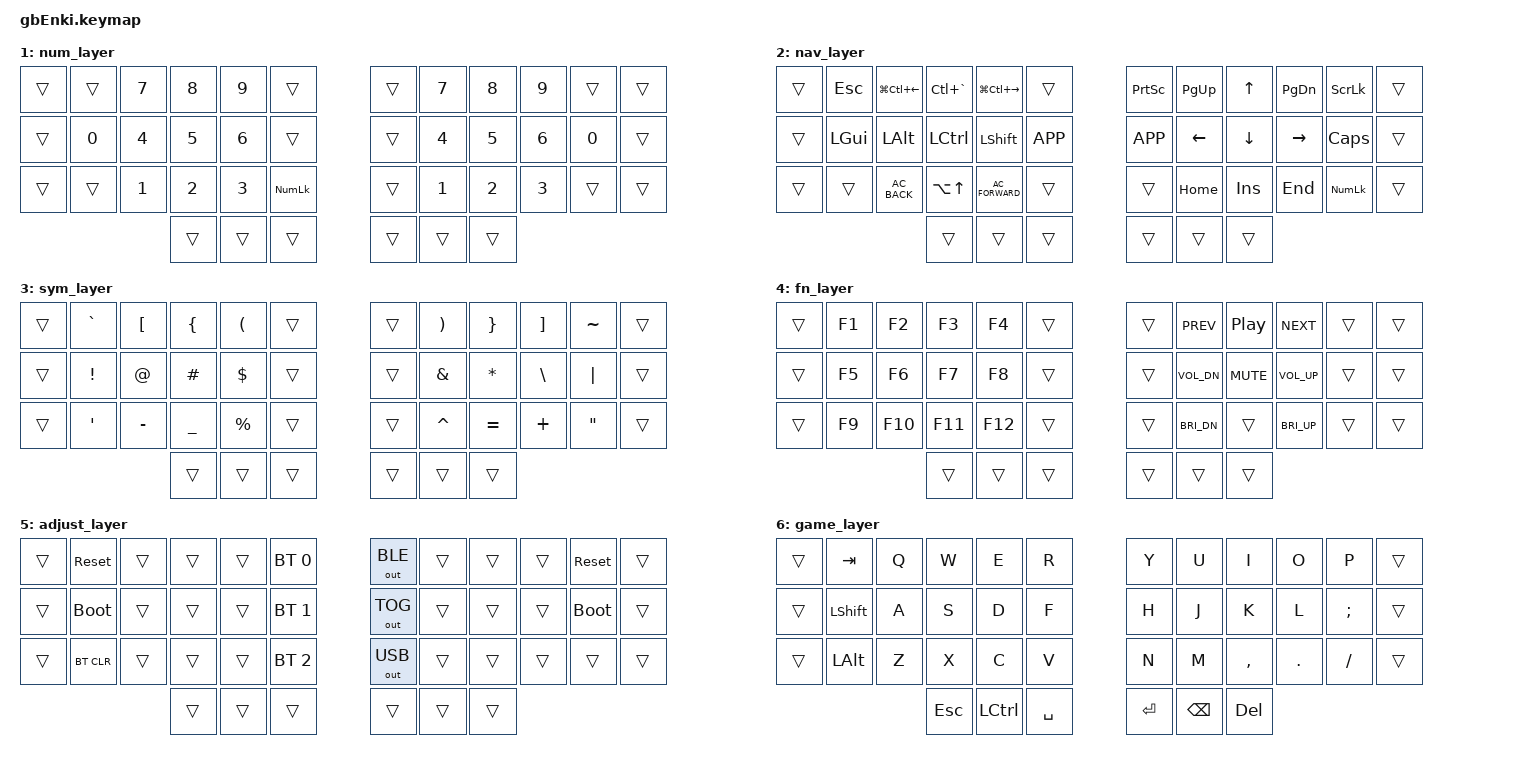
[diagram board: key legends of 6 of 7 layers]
// Copyright (c) 2022 The ZMK Contributors
// SPDX-License-Identifier: MIT

#include <behaviors.dtsi>
#include <dt-bindings/zmk/keys.h>
#include <dt-bindings/zmk/bt.h>
#include <dt-bindings/zmk/outputs.h>
#include <dt-bindings/zmk/ext_power.h>

#define HRML(k1,k2,k3,k4) &ht LGUI k1  &ht LALT k2  &ht LCTRL k3  &ht LSHFT k4
#define HRMR(k1,k2,k3,k4) &ht RSHFT k1  &ht RCTRL k2  &ht RALT k3  &ht RGUI k4
#define TERM &kp LC(GRAVE)
#define TASK_V &kp LG(TAB)
#define DESK_P &kp LG(LC(LEFT))
#define DESK_N &kp LG(LC(RIGHT))

#define COMBO(NAME, BINDINGS, KEYPOS, LAYERS) \
    combo_##NAME { \
        timeout-ms = <50>; \
        bindings = <BINDINGS>; \
        key-positions = <KEYPOS>; \
        layers = <LAYERS>; \
    };

/ {
    behaviors {
        ht: hold_tap {
            label = "hold_tap";
            compatible = "zmk,behavior-hold-tap";
            #binding-cells = <2>;
            flavor = "tap-preferred";
            tapping-term-ms = <150>;
            quick-tap-ms = <250>;
            bindings = <&kp>, <&kp>;
        };
        tt: thumb_hold_tap {
            label = "thumb_hold_tap";
            compatible = "zmk,behavior-hold-tap";
            #binding-cells = <2>;
            flavor = "tap-preferred";
            tapping_term_ms = <150>;
            quick_tap_ms = <250>;
            bindings = <&mo>, <&kp>;
        };
    };

    conditional_layers {
        compatible = "zmk,conditional-layers";
        adjust_layer {
            if-layers = <2 3>;
            then-layer = <5>;
        };
    };

        //╭──────╭──────┬──────┬──────┬──────┬──────╮   ╭──────┬──────┬──────┬──────┬──────╮──────╮
        //│  0   │  1   │  2   │  3   │  4   │  5   │   │  6   │  7   │  8   │  9   │  10  │  11  │
        //├──────├──────┼──────┼──────┼──────┼──────┤   ├──────┼──────┼──────┼──────┼──────┤──────┤
        //│  12  │  13  │  14  │  15  │  16  │  17  │   │  18  │  19  │  20  │  21  │  22  │  23  │
        //├──────├──────┼──────┼──────┼──────┼──────┤   ├──────┼──────┼──────┼──────┼──────┤──────┤
        //│  24  │  25  │  26  │  27  │  28  │  29  │   │  30  │  31  │  32  │  33  │  34  │  35  │
        //╰──────╰──────┴──────┼──────┼──────┼──────┤   ├──────┼──────┼──────┼──────┴──────╯──────╯
        //                     |  36  |  37  |  38  |   |  39  |  40  |  41  |
        //                     ╰──────┴──────┴──────╯   ╰──────┴──────┴──────╯

    combos {
        compatible = "zmk,combos";
            // main
        COMBO(enter,              &kp RET,          15 16,        0)
        COMBO(backspace,          &kp BSPC,         14 15,        0)
        COMBO(delete,             &kp DEL,          14 16,        0)
            // game
        COMBO(game,               &tog 6,            1 38,        0 6)
            // num
        COMBO(num_space_l,        &kp SPACE,        15 16,        1)
        COMBO(num_dot_l,          &kp DOT,          14 15,        1)
        COMBO(num_comma_l,        &kp COMMA,        14 16,        1)
        COMBO(num_space_r,        &kp SPACE,        19 20,        1)
        COMBO(num_dot_r,          &kp DOT,          20 21,        1)
        COMBO(num_comma_r,        &kp COMMA,        19 21,        1)
            // nav
        COMBO(nav_taskv,          TASK_V,            2  4,        2)
    };

    keymap {
        compatible = "zmk,keymap";

        // - 0
        default_layer {
            bindings = <
        //╭──────────╭──────────┬──────────┬──────────┬──────────┬──────────╮   ╭──────────┬──────────┬──────────┬──────────┬──────────╮──────────╮
        //│  [       │  Q       │  W       │  E       │  R       │  T       │   │  Y       │  U       │  I       │  O       │  P       │  ]       │
            &kp LBKT   &kp Q      &kp W      &kp E      &kp R      &kp T          &kp Y      &kp U      &kp I      &kp O      &kp P      &kp RBKT
        //├──────────├──────────┼──────────┼──────────┼──────────┼──────────┤   ├──────────┼──────────┼──────────┼──────────┼──────────┤──────────┤
        //│  `       │  A       │  S       │  D       │  F       │  G       │   │  H       │  J       │  K       │  L       │  ;       │  '       │
            &kp GRAVE   HRML(A,        S,         D,         F)     &kp G          &kp H      HRMR(J,        K,         L,        SEMI)  &kp SQT
        //├──────────├──────────┼──────────┼──────────┼──────────┼──────────┤   ├──────────┼──────────┼──────────┼──────────┼──────────┤──────────┤
        //│  |       │  Z       │  X       │  C       │  V       │  B       │   │  N       │  M       │ , <      │ . >      │ / ?      │  \       │
            &kp PIPE   &kp Z      &kp X      &kp C      &kp V      &kp B          &kp N      &kp M      &kp COMMA  &kp DOT    &kp FSLH   &kp BSLH
        //╰──────────╰──────────┴──────────┴──────────┼──────────┼──────────┤   ├──────────┼──────────┼──────────┴──────────┴──────────╯──────────╯
                                             &tt 4 ESC &tt 1 TAB  &tt 2 SPACE    &tt 3 RET  &tt 4 BSPC  &kp DEL
        //                                 ╰──────────┴──────────┴──────────╯   ╰──────────┴──────────┴──────────╯
            >;
        };

        // - 1
        num_layer {
            bindings = <
        //╭──────────╭──────────┬──────────┬──────────┬──────────┬──────────╮   ╭──────────┬──────────┬──────────┬──────────┬──────────╮──────────╮
        //│          │          │  7       │  8       │  9       │          │   │          │  7       │  8       │  9       │          │          │
            &trans     &trans     &kp N7     &kp N8     &kp N9     &trans         &trans     &kp N7     &kp N8     &kp N9     &trans     &trans
        //├──────────├──────────┼──────────┼──────────┼──────────┼──────────┤   ├──────────┼──────────┼──────────┼──────────┼──────────┤──────────┤
        //│          │  0       │  4       │  5       │  6       │          │   │          │  4       │  5       │  6       │  0       │          │
            &trans     &kp N0     &kp N4     &kp N5     &kp N6     &trans         &trans     &kp N4     &kp N5     &kp N6     &kp N0     &trans
        //├──────────├──────────┼──────────┼──────────┼──────────┼──────────┤   ├──────────┼──────────┼──────────┼──────────┼──────────┤──────────┤
        //│          │          │  1       │  2       │  3       │ NLCK     │   │          │  1       │  2       │  3       │          │          │
            &trans     &trans     &kp N1     &kp N2     &kp N3     &kp KP_NUM     &trans     &kp N1     &kp N2     &kp N3     &trans     &trans
        //╰──────────╰──────────┴──────────┴──────────┼──────────┼──────────┤   ├──────────┼──────────┼──────────┴──────────┴──────────╯──────────╯
                                             &trans     &trans     &trans         &trans     &trans     &trans
        //                                 ╰──────────┴──────────┴──────────╯   ╰──────────┴──────────┴──────────╯
            >;
        };

        // - 2
        nav_layer {
            bindings = <
        //╭──────────╭──────────┬──────────┬──────────┬──────────┬──────────╮   ╭──────────┬──────────┬──────────┬──────────┬──────────╮──────────╮
        //│          │ ESC      │ DESK <   │ TERMINAL │ DESK >   │          │   │ PRNT SCR │ PG_UP    │ UP       │ PG_DOWN  │ S_LCOK   │          │
            &trans     &kp ESC    DESK_P     TERM       DESK_N     &trans         &kp PSCRN  &kp PG_UP  &kp UP     &kp PG_DN  &kp SLCK   &trans
        //├──────────├──────────┼──────────┼──────────┼──────────┼──────────┤   ├──────────┼──────────┼──────────┼──────────┼──────────┤──────────┤
        //│          │ GUI      │ ALT      │ CTRL     │ SHIFT    │ APP      │   │ APP      │ LEFT     │ DOWN     │ RIGHT    │ C_LOCK   │          │
            &trans     &kp LGUI   &kp LALT   &kp LCTRL  &kp LSHFT  &kp K_APP      &kp K_APP  &kp LEFT   &kp DOWN   &kp RIGHT  &kp CLCK   &trans
        //├──────────├──────────┼──────────┼──────────┼──────────┼──────────┤   ├──────────┼──────────┼──────────┼──────────┼──────────┤──────────┤
        //│          │          │ BACK     │ UP       │ FORWARD  │          │   │          │ HOME     │ INSERT   │ END      │ N_LOCK   │          │
            &trans     &trans     &kp C_AC_BACK  &kp LA(UP)  &kp C_AC_FORWARD &trans  &trans &kp HOME   &kp INS    &kp END   &kp KP_NLCK &trans
        //╰──────────╰──────────┴──────────┴──────────┼──────────┼──────────┤   ├──────────┼──────────┼──────────┴──────────┴──────────╯──────────╯
                                             &trans     &trans     &trans         &trans     &trans     &trans
        //                                 ╰──────────┴──────────┴──────────╯   ╰──────────┴──────────┴──────────╯
            >;
        };

        // - 3
        sym_layer {
            bindings = <
        //╭──────────╭──────────┬──────────┬──────────┬──────────┬──────────╮   ╭──────────┬──────────┬──────────┬──────────┬──────────╮──────────╮
        //│          │  `       │  [       │  {       │  (       │          │   │          │  )       │  }       │  ]       │  ~       │          │
            &trans     &kp GRAVE  &kp LBKT   &kp LBRC   &kp LPAR   &trans         &trans     &kp RPAR   &kp RBRC   &kp RBKT   &kp TILDE  &trans
        //├──────────├──────────┼──────────┼──────────┼──────────┼──────────┤   ├──────────┼──────────┼──────────┼──────────┼──────────┤──────────┤
        //│          │  !       │  @       │  #       │  $       │          │   │          │  &       │  *       │  \       │  |       │          │
            &trans     &kp EXCL   &kp AT     &kp HASH   &kp DLLR   &trans         &trans     &kp AMPS   &kp ASTRK  &kp BSLH   &kp PIPE   &trans
        //├──────────├──────────┼──────────┼──────────┼──────────┼──────────┤   ├──────────┼──────────┼──────────┼──────────┼──────────┤──────────┤
        //│          │  '       │  -       │  _       │  %       │          │   │          │  ^       │  =       │  +       │  "       │          │
            &trans     &kp SQT    &kp MINUS  &kp UNDER  &kp PRCNT  &trans         &trans     &kp CARET  &kp EQUAL  &kp PLUS   &kp DQT    &trans
        //╰──────────╰──────────┴──────────┴──────────┼──────────┼──────────┤   ├──────────┼──────────┼──────────┴──────────┴──────────╯──────────╯
                                             &trans     &trans     &trans         &trans     &trans     &trans
        //                                 ╰──────────┴──────────┴──────────╯   ╰──────────┴──────────┴──────────╯
            >;
        };


        // - 4
        fn_layer {
            bindings = <
        //╭──────────╭──────────┬──────────┬──────────┬──────────┬──────────╮   ╭──────────┬──────────┬──────────┬──────────┬──────────╮──────────╮
        //│          │ F1       │ F2       │ F3       │ F4       │          │   │          │ <<<      │ P\P      │ >>>      │          │          │
            &trans     &kp F1     &kp F2     &kp F3     &kp F4     &trans         &trans     &kp C_PREV &kp C_PP   &kp C_NEXT &trans     &trans
        //├──────────├──────────┼──────────┼──────────┼──────────┼──────────┤   ├──────────┼──────────┼──────────┼──────────┼──────────┤──────────┤
        //│          │ F4       │ F5       │ F6       │ F8       │          │   │          │ VOL-     │ MUTE     │ VOL+     │          │          │
            &trans     &kp F5     &kp F6     &kp F7     &kp F8     &trans         &trans     &kp C_VOL_DN &kp C_MUTE &kp C_VOL_UP &trans &trans
        //├──────────├──────────┼──────────┼──────────┼──────────┼──────────┤   ├──────────┼──────────┼──────────┼──────────┼──────────┤──────────┤
        //│          │ F9       │ F10      │ F11      │ F12      │          │   │          │ BRI-     │          │ BRI+     │          │          │
            &trans     &kp F9     &kp F10    &kp F11    &kp F12    &trans         &trans     &kp C_BRI_DN &trans   &kp C_BRI_UP &trans   &trans
        //╰──────────╰──────────┴──────────┴──────────┼──────────┼──────────┤   ├──────────┼──────────┼──────────┴──────────┴──────────╯──────────╯
                                             &trans     &trans     &trans         &trans     &trans     &trans
        //                                 ╰──────────┴──────────┴──────────╯   ╰──────────┴──────────┴──────────╯
            >;
        };

        // - 5
        adjust_layer {
            bindings = <
        //╭──────────╭──────────┬──────────┬──────────┬──────────┬──────────╮   ╭──────────┬──────────┬──────────┬──────────┬──────────╮──────────╮
        //│          │  RESET   │          │          │          │PROFILE 0 │   │          │          │          │          │  RESET   │          │
            &trans    &sys_reset  &trans     &trans     &trans    &bt BT_SEL 0  &out OUT_BLE &trans     &trans     &trans    &sys_reset  &trans
        //├──────────├──────────┼──────────┼──────────┼──────────┼──────────┤   ├──────────┼──────────┼──────────┼──────────┼──────────┤──────────┤
        //│          │  BOOT    │          │          │          │PROFILE 1 │   │          │          │          │          │  BOOT    │          │
            &trans   &bootloader  &trans     &trans     &trans    &bt BT_SEL 1  &out OUT_TOG &trans     &trans     &trans    &bootloader &trans
        //├──────────├──────────┼──────────┼──────────┼──────────┼──────────┤   ├──────────┼──────────┼──────────┼──────────┼──────────┤──────────┤
        //│          │ CLEAR BT │          │          │          │PROFILE 2 │   │          │          │          │          │          │          │
            &trans     &bt BT_CLR  &trans     &trans    &trans    &bt BT_SEL 2  &out OUT_USB &trans     &trans     &trans     &trans     &trans
        //╰──────────╰──────────┴──────────┴──────────┼──────────┼──────────┤   ├──────────┼──────────┼──────────┴──────────┴──────────╯──────────╯
                                             &trans     &trans     &trans         &trans     &trans     &trans
        //                                 ╰──────────┴──────────┴──────────╯   ╰──────────┴──────────┴──────────╯
            >;
        };

        // - 6
        game_layer {
            bindings = <
        //╭──────────╭──────────┬──────────┬──────────┬──────────┬──────────╮   ╭──────────┬──────────┬──────────┬──────────┬──────────╮──────────╮
        //│          │  TAB     │  Q       │  W       │  E       │  R       │   │  Y       │  U       │  I       │  O       │  P       │          │
            &trans     &kp TAB    &kp Q      &kp W      &kp E      &kp R          &kp Y      &kp U      &kp I      &kp O      &kp P      &trans
        //├──────────├──────────┼──────────┼──────────┼──────────┼──────────┤   ├──────────┼──────────┼──────────┼──────────┼──────────┤──────────┤
        //│          │  SHIFT   │  A       │  S       │  D       │  F       │   │  H       │  J       │  K       │  L       │  ;       │          │
            &trans     &kp LSHFT  &kp A      &kp S      &kp D      &kp F          &kp H      &kp J      &kp K      &kp L      &kp SEMI   &trans
        //├──────────├──────────┼──────────┼──────────┼──────────┼──────────┤   ├──────────┼──────────┼──────────┼──────────┼──────────┤──────────┤
        //│          │  ALT     │  Z       │  X       │  C       │  V       │   │  N       │  M       │  ,       │  .       │  /       │          │
            &trans     &kp LALT   &kp Z      &kp X      &kp C      &kp V          &kp N      &kp M      &kp COMMA  &kp DOT    &kp FSLH   &trans
        //╰──────────╰──────────┴──────────┴──────────┼──────────┼──────────┤   ├──────────┼──────────┼──────────┴──────────┴──────────╯──────────╯
                                             &kp ESC    &kp LCTRL  &kp SPACE      &kp RET    &kp BSPC   &kp DEL
        //                                 ╰──────────┴──────────┴──────────╯   ╰──────────┴──────────┴──────────╯
            >;
        };

    };
};
